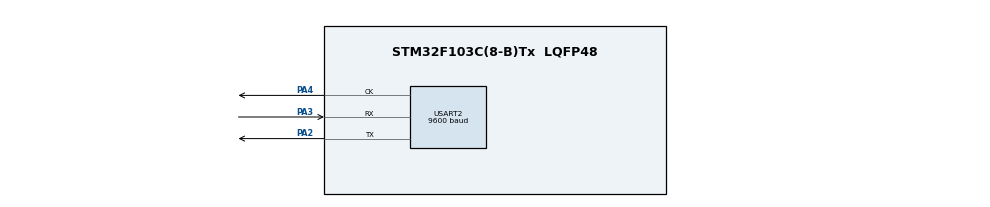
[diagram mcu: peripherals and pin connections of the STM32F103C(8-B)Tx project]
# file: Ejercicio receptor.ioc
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Mcu.Family=STM32F1
RCC.APB2Freq_Value=8000000
Mcu.Name=STM32F103C(8-B)Tx
PA2.Signal=USART2_TX
VP_SYS_VS_ND.Mode=No_Debug
PA4.Signal=USART2_CK
USART2.BaudRate=9600
Mcu.Package=LQFP48
ProjectManager.StackSize=0x400
USART2.VirtualMode=VM_SYNC
PA3.Mode=Synchronous
ProjectManager.HeapSize=0x200
PA4.Mode=Synchronous
ProjectManager.TargetToolchain=STM32CubeIDE
NVIC.PriorityGroup=NVIC_PRIORITYGROUP_4
PA2.Mode=Synchronous
RCC.APB1Freq_Value=8000000
PA3.Signal=USART2_RX
board=custom

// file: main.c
/* USER CODE BEGIN Header */
/**
  ******************************************************************************
  * @file           : main.c
  * @brief          : Main program body
  ******************************************************************************
  * @attention
  *
  * <h2><center>&copy; Copyright (c) 2021 STMicroelectronics.
  * All rights reserved.</center></h2>
  *
  * This software component is licensed by ST under BSD 3-Clause license,
  * the "License"; You may not use this file except in compliance with the
  * License. You may obtain a copy of the License at:
  *                        opensource.org/licenses/BSD-3-Clause
  *
  ******************************************************************************
  */
/* USER CODE END Header */
#include "main.h"

/* USER CODE BEGIN Includes */

#include <inttypes.h> //Libreria configurar enteros
#include <string.h> //Libreria manejo de caracteres
/* USER CODE END Includes */

UART_HandleTypeDef huart2;

void SystemClock_Config(void);
static void MX_GPIO_Init(void);
static void MX_USART2_UART_Init(void);

/* USER CODE BEGIN 0 */

char buffer[10]; //vector receptor
void HAL_UART_RxCpltCallback(UART_HandleTypeDef *huart)
{
  HAL_UART_Receive_IT(&huart2, buffer, 8); //recibe el vector
  HAL_UART_Transmit(&huart2, (uint8_t *)buffer, sizeof(buffer), 100); //Envia el vector
  HAL_UART_Transmit(&huart2, (uint8_t *)"\n", sizeof("\n"), 100); //Envia caracter final
  HAL_Delay(200); //Espera 200ms
}
/* USER CODE END 0 */

int main(void)
{
  /* USER CODE BEGIN 1 */
	HAL_UART_Receive_IT (&huart2, buffer, 8);

  /* USER CODE END 1 */

  /* MCU Configuration--------------------------------------------------------*/

  /* Reset of all peripherals, Initializes the Flash interface and the Systick. */
  HAL_Init();

  /* Configure the system clock */
  SystemClock_Config();

  /* Initialize all configured peripherals */
  MX_GPIO_Init();
  MX_USART2_UART_Init();

  /* Infinite loop */
  while (1)
  {

  }
}

void SystemClock_Config(void)
{
  RCC_OscInitTypeDef RCC_OscInitStruct = {0};
  RCC_ClkInitTypeDef RCC_ClkInitStruct = {0};
  RCC_PeriphCLKInitTypeDef PeriphClkInit = {0};

  /** Initializes the RCC Oscillators according to the specified parameters
  * in the RCC_OscInitTypeDef structure.
  */
  RCC_OscInitStruct.OscillatorType = RCC_OSCILLATORTYPE_MSI;
  RCC_OscInitStruct.MSIState = RCC_MSI_ON;
  RCC_OscInitStruct.MSICalibrationValue = 0;
  RCC_OscInitStruct.MSIClockRange = RCC_MSIRANGE_6;
  RCC_OscInitStruct.PLL.PLLState = RCC_PLL_NONE;
  if (HAL_RCC_OscConfig(&RCC_OscInitStruct) != HAL_OK)
  {
    Error_Handler();
  }
  /** Initializes the CPU, AHB and APB buses clocks
  */
  RCC_ClkInitStruct.ClockType = RCC_CLOCKTYPE_HCLK|RCC_CLOCKTYPE_SYSCLK
                              |RCC_CLOCKTYPE_PCLK1|RCC_CLOCKTYPE_PCLK2;
  RCC_ClkInitStruct.SYSCLKSource = RCC_SYSCLKSOURCE_MSI;
  RCC_ClkInitStruct.AHBCLKDivider = RCC_SYSCLK_DIV1;
  RCC_ClkInitStruct.APB1CLKDivider = RCC_HCLK_DIV1;
  RCC_ClkInitStruct.APB2CLKDivider = RCC_HCLK_DIV1;

  if (HAL_RCC_ClockConfig(&RCC_ClkInitStruct, FLASH_LATENCY_0) != HAL_OK)
  {
    Error_Handler();
  }
  PeriphClkInit.PeriphClockSelection = RCC_PERIPHCLK_USART2;
  PeriphClkInit.Usart2ClockSelection = RCC_USART2CLKSOURCE_PCLK1;
  if (HAL_RCCEx_PeriphCLKConfig(&PeriphClkInit) != HAL_OK)
  {
    Error_Handler();
  }
  /** Configure the main internal regulator output voltage
  */
  if (HAL_PWREx_ControlVoltageScaling(PWR_REGULATOR_VOLTAGE_SCALE1) != HAL_OK)
  {
    Error_Handler();
  }
}

static void MX_USART2_UART_Init(void)
{

  huart2.Instance = USART2;
  huart2.Init.BaudRate = 9600;
  huart2.Init.WordLength = UART_WORDLENGTH_8B;
  huart2.Init.StopBits = UART_STOPBITS_1;
  huart2.Init.Parity = UART_PARITY_NONE;
  huart2.Init.Mode = UART_MODE_TX_RX;
  huart2.Init.HwFlowCtl = UART_HWCONTROL_NONE;
  huart2.Init.OverSampling = UART_OVERSAMPLING_16;
  huart2.Init.OneBitSampling = UART_ONE_BIT_SAMPLE_DISABLE;
  huart2.AdvancedInit.AdvFeatureInit = UART_ADVFEATURE_NO_INIT;
  if (HAL_UART_Init(&huart2) != HAL_OK)
  {
    Error_Handler();
  }

}

static void MX_GPIO_Init(void)
{

  /* GPIO Ports Clock Enable */
  __HAL_RCC_GPIOA_CLK_ENABLE();

}

void Error_Handler(void)
{
  __disable_irq();
  while (1)
  {
  }
}

/************************ (C) COPYRIGHT STMicroelectronics *****END OF FILE****/
